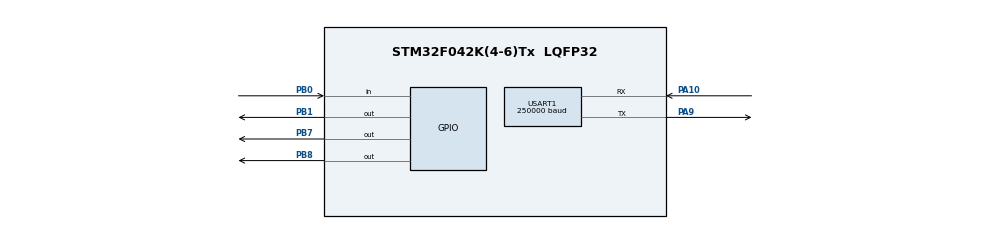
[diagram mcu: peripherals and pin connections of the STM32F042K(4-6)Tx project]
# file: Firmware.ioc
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Mcu.Family=STM32F0
Mcu.Name=STM32F042K(4-6)Tx
Mcu.Package=LQFP32
PA10.Mode=Asynchronous
PA10.Signal=USART1_RX
PA9.Mode=Asynchronous
PA9.Signal=USART1_TX
PB0.Signal=GPIO_Input
PB1.PinState=GPIO_PIN_SET
PB1.Signal=GPIO_Output
PB7.Signal=GPIO_Output
PB8.Signal=GPIO_Output
ProjectManager.HeapSize=0x200
ProjectManager.StackSize=0x400
ProjectManager.TargetToolchain=SW4STM32
TIM2.Channel-Output\ Compare1\ No\ Output=TIM_CHANNEL_1
TIM2.Prescaler=0x0008
USART1.BaudRate=250000
USART1.VirtualMode-Asynchronous=VM_ASYNC
VP_TIM2_VS_no_output1.Mode=Output Compare1 No Output
board=custom

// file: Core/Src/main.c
/* USER CODE BEGIN Header */
/**
  ******************************************************************************
  * @file           : main.c
  * @brief          : Main program body
  ******************************************************************************
  * @attention
  *
  * <h2><center>&copy; Copyright (c) 2021 STMicroelectronics.
  * All rights reserved.</center></h2>
  *
  * This software component is licensed by ST under BSD 3-Clause license,
  * the "License"; You may not use this file except in compliance with the
  * License. You may obtain a copy of the License at:
  *                        opensource.org/licenses/BSD-3-Clause
  *
  ******************************************************************************
  */
/* USER CODE END Header */
#include "main.h"
#include "string.h"

TIM_HandleTypeDef htim2;

UART_HandleTypeDef huart1;

void SystemClock_Config(void);
static void MX_GPIO_Init(void);
static void MX_USART1_UART_Init(void);
static void MX_TIM2_Init(void);

/* USER CODE BEGIN 0 */
void debugPrintln(UART_HandleTypeDef *huart, char _out[]);
void debugPrint(UART_HandleTypeDef *huart, char _out[]);
void delay_us(uint16_t us);
void bq79606_wake();
/* USER CODE END 0 */

int main(void)
{

  /* MCU Configuration--------------------------------------------------------*/

  /* Reset of all peripherals, Initializes the Flash interface and the Systick. */
  HAL_Init();

  /* Configure the system clock */
  SystemClock_Config();

  /* Initialize all configured peripherals */
  MX_GPIO_Init();
  MX_USART1_UART_Init();
  MX_TIM2_Init();

  /* USER CODE BEGIN 2 */

  bq79606_wake();

  /* USER CODE END 2 */

  /* Infinite loop */
  /* USER CODE BEGIN WHILE */
  uint8_t message[14] =
  {
		  0x8, 0x0,
		  0x0, 0x0,
		  0x0, 0x2, 0x1, 0x5,
		  0x0, 0xb,
		  0xc, 0xb, 0x4, 0x9
  };

  while (1)
  {

	  HAL_GPIO_WritePin(GPIOB, GPIO_PIN_8, GPIO_PIN_SET);
	  HAL_Delay(1000);

	  //HAL_UART_Transmit(&huart1, message, 14, 10);
	  //debugPrint(&huart1, "FUCK");

	  HAL_GPIO_WritePin(GPIOB, GPIO_PIN_8, GPIO_PIN_RESET);
	  HAL_Delay(1000);

  }
  /* USER CODE END 3 */
}

void delay_us (uint16_t us)
{
	__HAL_TIM_SET_COUNTER(&htim2,0);  // set the counter value a 0
	while (__HAL_TIM_GET_COUNTER(&htim2) < us);  // wait for the counter to reach the us input in the parameter
}

void bq79606_wake()
{
	  // WAKE the BMS IC
	  HAL_TIM_Base_Start(&htim2);
	  HAL_GPIO_WritePin(GPIOB, GPIO_PIN_1, GPIO_PIN_RESET);
	  delay_us(300);
	  HAL_GPIO_WritePin(GPIOB, GPIO_PIN_1, GPIO_PIN_SET);
}

void debugPrint(UART_HandleTypeDef *huart, char _out[])
{
	HAL_UART_Transmit(huart, (uint8_t *) _out, strlen(_out), 10);
}

void SystemClock_Config(void)
{
  RCC_OscInitTypeDef RCC_OscInitStruct = {0};
  RCC_ClkInitTypeDef RCC_ClkInitStruct = {0};
  RCC_PeriphCLKInitTypeDef PeriphClkInit = {0};

  /** Initializes the RCC Oscillators according to the specified parameters
  * in the RCC_OscInitTypeDef structure.
  */
  RCC_OscInitStruct.OscillatorType = RCC_OSCILLATORTYPE_HSI;
  RCC_OscInitStruct.HSIState = RCC_HSI_ON;
  RCC_OscInitStruct.HSICalibrationValue = RCC_HSICALIBRATION_DEFAULT;
  RCC_OscInitStruct.PLL.PLLState = RCC_PLL_NONE;
  if (HAL_RCC_OscConfig(&RCC_OscInitStruct) != HAL_OK)
  {
    Error_Handler();
  }
  /** Initializes the CPU, AHB and APB buses clocks
  */
  RCC_ClkInitStruct.ClockType = RCC_CLOCKTYPE_HCLK|RCC_CLOCKTYPE_SYSCLK
                              |RCC_CLOCKTYPE_PCLK1;
  RCC_ClkInitStruct.SYSCLKSource = RCC_SYSCLKSOURCE_HSI;
  RCC_ClkInitStruct.AHBCLKDivider = RCC_SYSCLK_DIV1;
  RCC_ClkInitStruct.APB1CLKDivider = RCC_HCLK_DIV1;

  if (HAL_RCC_ClockConfig(&RCC_ClkInitStruct, FLASH_LATENCY_0) != HAL_OK)
  {
    Error_Handler();
  }
  PeriphClkInit.PeriphClockSelection = RCC_PERIPHCLK_USART1;
  PeriphClkInit.Usart1ClockSelection = RCC_USART1CLKSOURCE_PCLK1;
  if (HAL_RCCEx_PeriphCLKConfig(&PeriphClkInit) != HAL_OK)
  {
    Error_Handler();
  }
}

static void MX_TIM2_Init(void)
{

  TIM_MasterConfigTypeDef sMasterConfig = {0};
  TIM_OC_InitTypeDef sConfigOC = {0};

  htim2.Instance = TIM2;
  htim2.Init.Prescaler = 0x0008;
  htim2.Init.CounterMode = TIM_COUNTERMODE_UP;
  htim2.Init.Period = 4294967295;
  htim2.Init.ClockDivision = TIM_CLOCKDIVISION_DIV1;
  htim2.Init.AutoReloadPreload = TIM_AUTORELOAD_PRELOAD_DISABLE;
  if (HAL_TIM_OC_Init(&htim2) != HAL_OK)
  {
    Error_Handler();
  }
  sMasterConfig.MasterOutputTrigger = TIM_TRGO_RESET;
  sMasterConfig.MasterSlaveMode = TIM_MASTERSLAVEMODE_DISABLE;
  if (HAL_TIMEx_MasterConfigSynchronization(&htim2, &sMasterConfig) != HAL_OK)
  {
    Error_Handler();
  }
  sConfigOC.OCMode = TIM_OCMODE_TIMING;
  sConfigOC.Pulse = 0;
  sConfigOC.OCPolarity = TIM_OCPOLARITY_HIGH;
  sConfigOC.OCFastMode = TIM_OCFAST_DISABLE;
  if (HAL_TIM_OC_ConfigChannel(&htim2, &sConfigOC, TIM_CHANNEL_1) != HAL_OK)
  {
    Error_Handler();
  }

}

static void MX_USART1_UART_Init(void)
{

  huart1.Instance = USART1;
  huart1.Init.BaudRate = 1000000;
  huart1.Init.WordLength = UART_WORDLENGTH_8B;
  huart1.Init.StopBits = UART_STOPBITS_1;
  huart1.Init.Parity = UART_PARITY_NONE;
  huart1.Init.Mode = UART_MODE_TX_RX;
  huart1.Init.HwFlowCtl = UART_HWCONTROL_NONE;
  huart1.Init.OverSampling = UART_OVERSAMPLING_16;
  huart1.Init.OneBitSampling = UART_ONE_BIT_SAMPLE_DISABLE;
  huart1.AdvancedInit.AdvFeatureInit = UART_ADVFEATURE_NO_INIT;
  if (HAL_UART_Init(&huart1) != HAL_OK)
  {
    Error_Handler();
  }

}

static void MX_GPIO_Init(void)
{
  GPIO_InitTypeDef GPIO_InitStruct = {0};

  /* GPIO Ports Clock Enable */
  __HAL_RCC_GPIOB_CLK_ENABLE();
  __HAL_RCC_GPIOA_CLK_ENABLE();

  /*Configure GPIO pin Output Level */
  HAL_GPIO_WritePin(GPIOB, GPIO_PIN_1, GPIO_PIN_SET);

  /*Configure GPIO pin Output Level */
  HAL_GPIO_WritePin(GPIOB, GPIO_PIN_7|GPIO_PIN_8, GPIO_PIN_RESET);

  /*Configure GPIO pin : PB0 */
  GPIO_InitStruct.Pin = GPIO_PIN_0;
  GPIO_InitStruct.Mode = GPIO_MODE_INPUT;
  GPIO_InitStruct.Pull = GPIO_NOPULL;
  HAL_GPIO_Init(GPIOB, &GPIO_InitStruct);

  /*Configure GPIO pins : PB1 PB7 PB8 */
  GPIO_InitStruct.Pin = GPIO_PIN_1|GPIO_PIN_7|GPIO_PIN_8;
  GPIO_InitStruct.Mode = GPIO_MODE_OUTPUT_PP;
  GPIO_InitStruct.Pull = GPIO_NOPULL;
  GPIO_InitStruct.Speed = GPIO_SPEED_FREQ_LOW;
  HAL_GPIO_Init(GPIOB, &GPIO_InitStruct);

}

void Error_Handler(void)
{
  __disable_irq();
  while (1)
  {
  }
}

/************************ (C) COPYRIGHT STMicroelectronics *****END OF FILE****/
